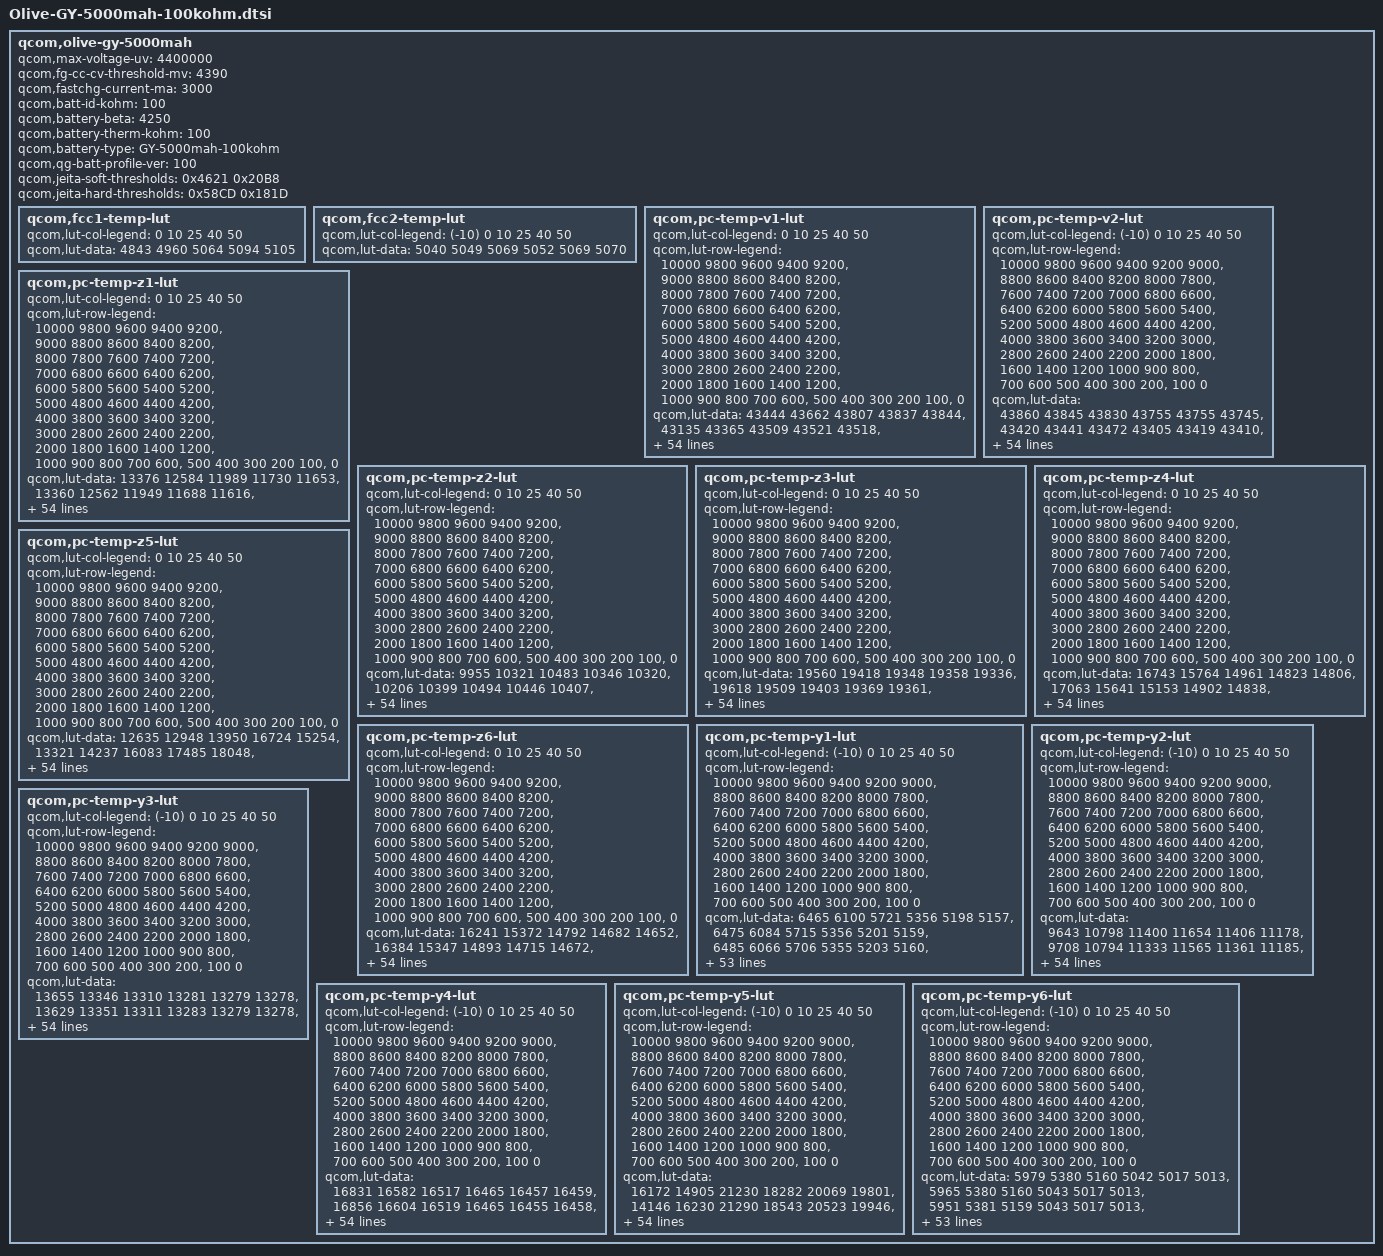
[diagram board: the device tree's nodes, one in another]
/* Copyright (c) 2018, The Linux Foundation. All rights reserved.
 * Copyright (C) 2021 XiaoMi, Inc.
 *
 * This program is free software; you can redistribute it and/or modify
 * it under the terms of the GNU General Public License version 2 and
 * only version 2 as published by the Free Software Foundation.
 *
 * This program is distributed in the hope that it will be useful,
 * but WITHOUT ANY WARRANTY; without even the implied warranty of
 * MERCHANTABILITY or FITNESS FOR A PARTICULAR PURPOSE.  See the
 * GNU General Public License for more details.
 */

qcom,olive-gy-5000mah {
	/* Peony-GY-5000mah-100kohm_Master_2018.12.27 */
	qcom,max-voltage-uv = <4400000>;
	qcom,fg-cc-cv-threshold-mv = <4390>;
	qcom,fastchg-current-ma = <3000>;
	qcom,batt-id-kohm = <100>;
	qcom,battery-beta = <4250>;
	qcom,battery-therm-kohm = <100>;
	qcom,battery-type =
		"GY-5000mah-100kohm";
	qcom,qg-batt-profile-ver = <100>;

/*	qcom,jeita-fcc-ranges = <0   50   400000
				 51  100  1200000
				 101 150  1950000
				 151 450  2000000
				 451 550  1000000
				 551 600  0>;
	qcom,jeita-fv-ranges =  <0   50   4400000
				 51  100  4400000
				 101 150  4400000
				 151 450  4400000
				 451 550  4100000
				 551 600  4100000>;*/

	/* COOL = 15 DegC, WARM = 45 DegC */
	qcom,jeita-soft-thresholds = <0x4621 0x20B8>;
	/* COLD = 0 DegC, HOT = 55 DegC */
	qcom,jeita-hard-thresholds = <0x58CD 0x181D>;

	qcom,fcc1-temp-lut {
		qcom,lut-col-legend = <0 10 25 40 50>;
		qcom,lut-data = <4843 4960 5064 5094 5105>;
	};

	qcom,fcc2-temp-lut {
		qcom,lut-col-legend = <(-10) 0 10 25 40 50>;
		qcom,lut-data = <5040 5049 5069 5052 5069 5070>;
	};

	qcom,pc-temp-v1-lut {
		qcom,lut-col-legend = <0 10 25 40 50>;
		qcom,lut-row-legend = <10000 9800 9600 9400 9200>,
			<9000 8800 8600 8400 8200>,
			<8000 7800 7600 7400 7200>,
			<7000 6800 6600 6400 6200>,
			<6000 5800 5600 5400 5200>,
			<5000 4800 4600 4400 4200>,
			<4000 3800 3600 3400 3200>,
			<3000 2800 2600 2400 2200>,
			<2000 1800 1600 1400 1200>,
			<1000 900 800 700 600>,
			<500 400 300 200 100>,
			<0>;
		qcom,lut-data = <43444 43662 43807 43837 43844>,
			<43135 43365 43509 43521 43518>,
			<42862 43088 43238 43251 43245>,
			<42607 42832 42978 42997 42993>,
			<42368 42590 42726 42749 42748>,
			<42143 42354 42483 42510 42510>,
			<41926 42124 42247 42276 42277>,
			<41711 41900 42020 42042 42042>,
			<41502 41678 41796 41812 41812>,
			<41314 41462 41568 41584 41587>,
			<41165 41270 41344 41359 41366>,
			<41006 41114 41146 41143 41149>,
			<40760 40947 40979 40939 40934>,
			<40419 40685 40792 40739 40726>,
			<40142 40347 40517 40529 40524>,
			<39960 40101 40221 40318 40330>,
			<39815 39950 40035 40131 40147>,
			<39689 39823 39912 39967 39977>,
			<39583 39696 39790 39812 39814>,
			<39478 39577 39653 39665 39662>,
			<39360 39452 39507 39519 39516>,
			<39241 39320 39341 39334 39334>,
			<39126 39180 39153 39081 39078>,
			<39014 39011 38961 38861 38850>,
			<38907 38811 38752 38719 38716>,
			<38807 38643 38570 38606 38612>,
			<38711 38504 38475 38504 38511>,
			<38620 38394 38414 38413 38412>,
			<38530 38325 38355 38331 38322>,
			<38447 38276 38292 38256 38244>,
			<38378 38236 38232 38190 38174>,
			<38316 38204 38179 38129 38109>,
			<38265 38175 38131 38075 38052>,
			<38225 38147 38086 38024 37997>,
			<38191 38122 38046 37980 37948>,
			<38158 38095 38008 37937 37901>,
			<38129 38069 37973 37892 37850>,
			<38096 38037 37939 37847 37798>,
			<38055 37989 37890 37789 37733>,
			<38003 37914 37811 37708 37644>,
			<37931 37822 37715 37611 37541>,
			<37814 37710 37609 37506 37434>,
			<37675 37578 37484 37384 37313>,
			<37513 37415 37326 37224 37153>,
			<37373 37271 37178 37083 37011>,
			<37260 37170 37076 36993 36932>,
			<37219 37135 37051 36966 36908>,
			<37184 37119 37028 36944 36885>,
			<37155 37096 37009 36924 36866>,
			<37118 37067 36980 36891 36823>,
			<36978 36919 36810 36684 36588>,
			<36569 36495 36395 36262 36161>,
			<35999 35931 35828 35692 35592>,
			<35231 35161 35051 34912 34809>,
			<34016 33956 33853 33702 33594>,
			<30000 30000 30000 30000 30000>;
	};

	qcom,pc-temp-v2-lut {
		qcom,lut-col-legend = <(-10) 0 10 25 40 50>;
		qcom,lut-row-legend = <10000 9800 9600 9400 9200 9000>,
			<8800 8600 8400 8200 8000 7800>,
			<7600 7400 7200 7000 6800 6600>,
			<6400 6200 6000 5800 5600 5400>,
			<5200 5000 4800 4600 4400 4200>,
			<4000 3800 3600 3400 3200 3000>,
			<2800 2600 2400 2200 2000 1800>,
			<1600 1400 1200 1000 900 800>,
			<700 600 500 400 300 200>,
			<100 0>;
		qcom,lut-data = <43860 43845 43830 43755 43755 43745>,
			<43420 43441 43472 43405 43419 43410>,
			<43036 43086 43149 43088 43112 43104>,
			<42715 42788 42865 42810 42838 42831>,
			<42443 42538 42617 42567 42594 42588>,
			<42203 42299 42378 42332 42357 42352>,
			<41999 42062 42141 42096 42120 42116>,
			<41807 41831 41909 41863 41887 41884>,
			<41568 41604 41682 41636 41658 41654>,
			<41275 41378 41459 41411 41432 41427>,
			<41079 41177 41248 41195 41210 41205>,
			<41011 41022 41062 40999 40994 40988>,
			<40951 40866 40876 40804 40782 40775>,
			<40702 40623 40646 40577 40574 40571>,
			<40059 40275 40379 40320 40369 40370>,
			<39605 39970 40136 40106 40177 40180>,
			<39434 39736 39926 39946 40001 39997>,
			<39306 39535 39733 39805 39833 39824>,
			<39154 39362 39554 39660 39673 39661>,
			<38996 39213 39387 39519 39520 39509>,
			<38840 39061 39213 39352 39351 39344>,
			<38687 38896 39018 39129 39156 39162>,
			<38542 38737 38834 38900 38957 38974>,
			<38411 38596 38683 38716 38763 38776>,
			<38291 38467 38549 38555 38574 38577>,
			<38197 38344 38428 38423 38431 38428>,
			<38127 38222 38317 38317 38324 38320>,
			<38068 38115 38216 38225 38232 38227>,
			<38012 38036 38128 38140 38145 38138>,
			<37962 37972 38048 38063 38066 38058>,
			<37913 37920 37976 37995 37998 37988>,
			<37864 37876 37908 37932 37939 37927>,
			<37815 37839 37853 37876 37882 37870>,
			<37764 37807 37809 37824 37825 37814>,
			<37712 37778 37773 37777 37767 37758>,
			<37660 37740 37739 37730 37700 37683>,
			<37607 37691 37707 37683 37623 37585>,
			<37552 37635 37671 37631 37543 37488>,
			<37491 37576 37623 37566 37469 37406>,
			<37428 37511 37562 37490 37395 37329>,
			<37364 37433 37489 37409 37318 37251>,
			<37300 37333 37394 37322 37236 37171>,
			<37234 37227 37276 37210 37122 37060>,
			<37164 37122 37138 37068 36980 36922>,
			<37082 37030 37011 36942 36859 36800>,
			<36984 36934 36921 36879 36812 36757>,
			<36926 36890 36901 36868 36802 36747>,
			<36862 36845 36879 36851 36788 36732>,
			<36793 36789 36849 36827 36765 36708>,
			<36690 36715 36789 36773 36696 36629>,
			<36493 36549 36618 36567 36439 36337>,
			<36136 36190 36182 36095 35935 35828>,
			<35592 35612 35537 35467 35280 35164>,
			<34770 34782 34679 34610 34374 34245>,
			<33376 33455 33434 33276 33046 32880>,
			<28527 28294 28305 28229 28383 28334>;
	};

	qcom,pc-temp-z1-lut {
		qcom,lut-col-legend = <0 10 25 40 50>;
		qcom,lut-row-legend = <10000 9800 9600 9400 9200>,
			<9000 8800 8600 8400 8200>,
			<8000 7800 7600 7400 7200>,
			<7000 6800 6600 6400 6200>,
			<6000 5800 5600 5400 5200>,
			<5000 4800 4600 4400 4200>,
			<4000 3800 3600 3400 3200>,
			<3000 2800 2600 2400 2200>,
			<2000 1800 1600 1400 1200>,
			<1000 900 800 700 600>,
			<500 400 300 200 100>,
			<0>;
		qcom,lut-data = <13376 12584 11989 11730 11653>,
			<13360 12562 11949 11688 11616>,
			<13341 12545 11931 11676 11606>,
			<13316 12531 11922 11669 11600>,
			<13301 12521 11915 11665 11597>,
			<13300 12515 11909 11662 11595>,
			<13306 12504 11905 11660 11595>,
			<13308 12495 11903 11659 11596>,
			<13310 12494 11901 11658 11598>,
			<13307 12496 11903 11659 11600>,
			<13294 12495 11906 11661 11602>,
			<13274 12485 11907 11662 11603>,
			<13249 12471 11906 11663 11603>,
			<13215 12453 11905 11663 11603>,
			<13183 12431 11895 11663 11603>,
			<13151 12425 11881 11661 11604>,
			<13127 12428 11880 11660 11604>,
			<13127 12434 11887 11662 11606>,
			<13148 12441 11894 11664 11607>,
			<13162 12453 11900 11665 11608>,
			<13154 12465 11905 11667 11609>,
			<13137 12475 11909 11668 11610>,
			<13131 12483 11911 11669 11611>,
			<13124 12488 11914 11670 11611>,
			<13122 12492 11917 11672 11613>,
			<13140 12494 11920 11674 11615>,
			<13179 12500 11923 11677 11617>,
			<13195 12508 11926 11680 11620>,
			<13185 12511 11930 11682 11623>,
			<13174 12512 11933 11686 11625>,
			<13176 12513 11937 11689 11627>,
			<13185 12520 11941 11692 11629>,
			<13192 12529 11945 11694 11631>,
			<13200 12540 11950 11697 11633>,
			<13209 12554 11957 11700 11635>,
			<13222 12568 11965 11703 11638>,
			<13247 12580 11974 11707 11641>,
			<13267 12592 11983 11710 11643>,
			<13273 12602 11990 11713 11646>,
			<13276 12611 11993 11716 11648>,
			<13281 12619 11996 11720 11650>,
			<13295 12628 12000 11724 11652>,
			<13297 12633 12004 11729 11655>,
			<13249 12622 12009 11732 11657>,
			<13265 12629 12017 11735 11659>,
			<13292 12643 12024 11736 11660>,
			<13308 12647 12021 11736 11659>,
			<13316 12632 12025 11737 11659>,
			<13298 12631 12023 11738 11661>,
			<13277 12638 12037 11742 11665>,
			<13282 12658 12039 11749 11670>,
			<13306 12651 12048 11757 11675>,
			<13288 12695 12060 11767 11684>,
			<13350 12713 12097 11782 11697>,
			<13350 12713 12097 11782 11697>,
			<13350 12713 12097 11782 11697>;
	};

	qcom,pc-temp-z2-lut {
		qcom,lut-col-legend = <0 10 25 40 50>;
		qcom,lut-row-legend = <10000 9800 9600 9400 9200>,
			<9000 8800 8600 8400 8200>,
			<8000 7800 7600 7400 7200>,
			<7000 6800 6600 6400 6200>,
			<6000 5800 5600 5400 5200>,
			<5000 4800 4600 4400 4200>,
			<4000 3800 3600 3400 3200>,
			<3000 2800 2600 2400 2200>,
			<2000 1800 1600 1400 1200>,
			<1000 900 800 700 600>,
			<500 400 300 200 100>,
			<0>;
		qcom,lut-data = <9955 10321 10483 10346 10320>,
			<10206 10399 10494 10446 10407>,
			<10190 10431 10575 10529 10509>,
			<10138 10414 10608 10610 10572>,
			<10124 10392 10598 10616 10577>,
			<10130 10373 10575 10594 10550>,
			<10137 10356 10637 10566 10527>,
			<10145 10340 11160 10518 10521>,
			<10153 10325 11560 10476 10516>,
			<10164 10310 11404 10480 10497>,
			<10183 10304 11098 10504 10445>,
			<10201 10392 11062 10514 10421>,
			<10208 10490 11305 10491 10453>,
			<10209 10463 11454 10468 10493>,
			<10207 10357 11142 10487 10499>,
			<10195 10313 10685 10537 10499>,
			<10180 10318 10575 10547 10493>,
			<10170 10328 10553 10478 10454>,
			<10162 10350 10546 10420 10418>,
			<10158 10394 10577 10433 10424>,
			<10156 10434 10636 10477 10451>,
			<10155 10468 10698 10572 10521>,
			<10155 10502 10776 10853 10835>,
			<10156 10540 10808 11036 11074>,
			<10158 10582 10748 10854 10918>,
			<10162 10597 10667 10559 10624>,
			<10171 10584 10640 10543 10569>,
			<10183 10570 10623 10741 10627>,
			<10201 10577 10618 10857 10664>,
			<10221 10608 10633 10745 10553>,
			<10239 10625 10653 10580 10378>,
			<10255 10626 10664 10522 10324>,
			<10270 10626 10672 10492 10305>,
			<10284 10628 10682 10478 10306>,
			<10298 10633 10696 10478 10331>,
			<10312 10640 10714 10487 10372>,
			<10326 10653 10734 10509 10430>,
			<10339 10673 10759 10554 10513>,
			<10304 10701 10785 10600 10568>,
			<10229 10744 10820 10662 10605>,
			<10222 10772 10846 10705 10627>,
			<10275 10782 10856 10695 10619>,
			<10311 10788 10862 10676 10604>,
			<10334 10792 10860 10722 10607>,
			<9935 10894 10871 10724 10610>,
			<9845 11000 10909 10673 10607>,
			<9845 10996 10883 10678 10595>,
			<9868 11428 10883 10701 10605>,
			<9872 11696 10904 10701 10649>,
			<9952 11776 10951 10811 10727>,
			<9929 11691 10930 10738 10629>,
			<9791 11079 10876 10565 10428>,
			<9875 10983 10780 10486 10353>,
			<9585 10940 10681 10408 10259>,
			<9585 10940 10681 10408 10259>,
			<9585 10940 10681 10408 10259>;
	};

	qcom,pc-temp-z3-lut {
		qcom,lut-col-legend = <0 10 25 40 50>;
		qcom,lut-row-legend = <10000 9800 9600 9400 9200>,
			<9000 8800 8600 8400 8200>,
			<8000 7800 7600 7400 7200>,
			<7000 6800 6600 6400 6200>,
			<6000 5800 5600 5400 5200>,
			<5000 4800 4600 4400 4200>,
			<4000 3800 3600 3400 3200>,
			<3000 2800 2600 2400 2200>,
			<2000 1800 1600 1400 1200>,
			<1000 900 800 700 600>,
			<500 400 300 200 100>,
			<0>;
		qcom,lut-data = <19560 19418 19348 19358 19336>,
			<19618 19509 19403 19369 19361>,
			<19603 19562 19424 19383 19373>,
			<19574 19572 19434 19390 19379>,
			<19566 19578 19435 19391 19382>,
			<19567 19579 19435 19391 19384>,
			<19570 19576 19438 19391 19385>,
			<19573 19572 19448 19390 19387>,
			<19578 19566 19456 19388 19388>,
			<19582 19557 19450 19386 19386>,
			<19586 19551 19440 19383 19379>,
			<19591 19543 19437 19379 19374>,
			<19602 19538 19437 19372 19372>,
			<19622 19536 19435 19367 19370>,
			<19631 19530 19428 19368 19369>,
			<19623 19521 19419 19371 19366>,
			<19609 19501 19410 19371 19363>,
			<19598 19481 19399 19365 19358>,
			<19589 19473 19391 19357 19352>,
			<19582 19469 19385 19352 19347>,
			<19580 19466 19382 19348 19342>,
			<19580 19463 19384 19349 19342>,
			<19582 19461 19394 19364 19355>,
			<19586 19464 19399 19374 19364>,
			<19591 19475 19396 19361 19352>,
			<19594 19480 19391 19340 19330>,
			<19597 19478 19387 19341 19331>,
			<19599 19476 19383 19368 19366>,
			<19600 19475 19382 19384 19388>,
			<19601 19474 19385 19383 19384>,
			<19599 19473 19390 19381 19376>,
			<19595 19471 19392 19378 19370>,
			<19589 19468 19394 19373 19364>,
			<19582 19465 19394 19367 19359>,
			<19574 19461 19393 19362 19351>,
			<19565 19457 19391 19357 19343>,
			<19556 19453 19388 19352 19338>,
			<19544 19450 19383 19348 19335>,
			<19510 19446 19380 19347 19334>,
			<19460 19444 19379 19346 19334>,
			<19443 19441 19377 19346 19335>,
			<19441 19436 19374 19344 19335>,
			<19438 19432 19370 19341 19336>,
			<19431 19430 19369 19345 19339>,
			<19314 19415 19366 19344 19341>,
			<19275 19395 19361 19337 19334>,
			<19271 19392 19353 19332 19326>,
			<19271 19308 19352 19329 19323>,
			<19270 19293 19348 19328 19316>,
			<19266 19275 19347 19318 19310>,
			<19266 19297 19346 19330 19324>,
			<19274 19382 19351 19340 19338>,
			<19298 19364 19348 19342 19336>,
			<19282 19330 19354 19343 19337>,
			<19282 19330 19354 19343 19337>,
			<19282 19330 19354 19343 19337>;
	};

	qcom,pc-temp-z4-lut {
		qcom,lut-col-legend = <0 10 25 40 50>;
		qcom,lut-row-legend = <10000 9800 9600 9400 9200>,
			<9000 8800 8600 8400 8200>,
			<8000 7800 7600 7400 7200>,
			<7000 6800 6600 6400 6200>,
			<6000 5800 5600 5400 5200>,
			<5000 4800 4600 4400 4200>,
			<4000 3800 3600 3400 3200>,
			<3000 2800 2600 2400 2200>,
			<2000 1800 1600 1400 1200>,
			<1000 900 800 700 600>,
			<500 400 300 200 100>,
			<0>;
		qcom,lut-data = <16743 15764 14961 14823 14806>,
			<17063 15641 15153 14902 14838>,
			<16869 15508 15054 14875 14829>,
			<16485 15354 14940 14827 14802>,
			<16186 15193 14881 14795 14780>,
			<15941 15076 14835 14771 14760>,
			<15738 14992 14788 14751 14743>,
			<15593 14927 14734 14734 14727>,
			<15476 14882 14698 14721 14713>,
			<15367 14847 14690 14710 14704>,
			<15255 14809 14687 14700 14698>,
			<15162 14755 14678 14694 14693>,
			<15111 14715 14649 14689 14688>,
			<15077 14717 14631 14685 14684>,
			<15041 14736 14660 14682 14681>,
			<14992 14742 14704 14680 14678>,
			<14941 14729 14707 14677 14675>,
			<14902 14711 14680 14672 14673>,
			<14870 14697 14664 14667 14670>,
			<14845 14683 14663 14663 14666>,
			<14824 14678 14663 14661 14661>,
			<14808 14679 14666 14666 14664>,
			<14792 14679 14684 14711 14713>,
			<14777 14691 14709 14754 14760>,
			<14765 14729 14757 14777 14778>,
			<14755 14757 14802 14792 14789>,
			<14747 14780 14801 14786 14782>,
			<14743 14798 14779 14743 14729>,
			<14741 14795 14758 14708 14690>,
			<14740 14779 14740 14696 14684>,
			<14739 14762 14723 14687 14681>,
			<14738 14747 14709 14681 14678>,
			<14736 14732 14696 14677 14674>,
			<14732 14719 14687 14674 14671>,
			<14725 14707 14682 14671 14670>,
			<14718 14697 14679 14669 14669>,
			<14709 14687 14674 14669 14669>,
			<14704 14678 14670 14669 14669>,
			<14720 14675 14670 14669 14670>,
			<14754 14674 14672 14674 14678>,
			<14762 14672 14674 14679 14686>,
			<14755 14669 14670 14676 14682>,
			<14750 14666 14663 14670 14675>,
			<14747 14663 14662 14670 14677>,
			<14828 14653 14654 14665 14672>,
			<14856 14645 14637 14646 14650>,
			<14851 14643 14635 14642 14646>,
			<14845 14728 14625 14632 14636>,
			<14839 14739 14620 14617 14624>,
			<14836 14755 14616 14618 14618>,
			<14835 14733 14628 14631 14640>,
			<14849 14655 14638 14639 14648>,
			<14841 14685 14646 14643 14654>,
			<14879 14735 14645 14646 14656>,
			<14879 14735 14645 14646 14656>,
			<14879 14735 14645 14646 14656>;
	};

	qcom,pc-temp-z5-lut {
		qcom,lut-col-legend = <0 10 25 40 50>;
		qcom,lut-row-legend = <10000 9800 9600 9400 9200>,
			<9000 8800 8600 8400 8200>,
			<8000 7800 7600 7400 7200>,
			<7000 6800 6600 6400 6200>,
			<6000 5800 5600 5400 5200>,
			<5000 4800 4600 4400 4200>,
			<4000 3800 3600 3400 3200>,
			<3000 2800 2600 2400 2200>,
			<2000 1800 1600 1400 1200>,
			<1000 900 800 700 600>,
			<500 400 300 200 100>,
			<0>;
		qcom,lut-data = <12635 12948 13950 16724 15254>,
			<13321 14237 16083 17485 18048>,
			<13961 15265 17400 19047 20157>,
			<14582 15968 18497 20427 21430>,
			<15144 16526 19398 21266 22551>,
			<15697 17183 20211 21834 23491>,
			<16165 17987 21558 22358 24446>,
			<16491 18824 24203 22856 26139>,
			<16753 19588 26609 23376 27805>,
			<17028 20320 27953 24190 27913>,
			<17305 21290 29196 25256 27397>,
			<17614 23902 31465 25600 27153>,
			<18082 26453 38373 25009 28041>,
			<18742 27752 42852 24419 29436>,
			<19132 29407 39673 25956 30566>,
			<19247 29401 34097 29764 31651>,
			<19318 27059 31344 30902 31920>,
			<19341 24936 29576 29655 30729>,
			<19435 25873 28892 28420 29590>,
			<19642 29364 29841 28189 29632>,
			<20131 32240 32037 28416 29968>,
			<21010 33968 37204 30913 31464>,
			<22110 36106 49031 43554 40744>,
			<23800 43497 54609 52240 47979>,
			<25925 59489 46976 40972 38575>,
			<28408 65535 36005 22697 21154>,
			<31476 61517 30477 19875 18274>,
			<34895 54471 26417 23234 24491>,
			<39565 50797 25145 26433 29198>,
			<43666 48172 26020 28387 30006>,
			<45186 46202 27646 30123 30511>,
			<46151 44480 29973 31703 31267>,
			<46506 43206 33559 33231 32355>,
			<45564 42779 37145 34492 32823>,
			<43623 42710 41362 35680 31834>,
			<41746 42904 44177 36470 30643>,
			<39698 43510 44109 36456 30584>,
			<37040 44502 43592 36172 30760>,
			<31119 46089 43202 35796 30820>,
			<23308 48775 43022 35182 30534>,
			<21147 50087 42675 34266 30064>,
			<23073 46706 39973 32206 29402>,
			<24203 43792 36605 29916 28745>,
			<24295 44688 36805 33063 31919>,
			<15188 41948 37886 34598 35583>,
			<11871 32758 39032 31237 32125>,
			<11777 31755 31337 27297 25227>,
			<11764 13630 33448 27988 25484>,
			<11753 12893 32719 33863 26633>,
			<11721 12316 33738 26999 25972>,
			<11782 13433 28855 32013 30680>,
			<11946 23934 25540 27093 26201>,
			<12327 19240 21946 24254 21310>,
			<11762 14039 22225 21532 18748>,
			<11762 14039 22225 21532 18748>,
			<11762 14039 22225 21532 18748>;
	};

	qcom,pc-temp-z6-lut {
		qcom,lut-col-legend = <0 10 25 40 50>;
		qcom,lut-row-legend = <10000 9800 9600 9400 9200>,
			<9000 8800 8600 8400 8200>,
			<8000 7800 7600 7400 7200>,
			<7000 6800 6600 6400 6200>,
			<6000 5800 5600 5400 5200>,
			<5000 4800 4600 4400 4200>,
			<4000 3800 3600 3400 3200>,
			<3000 2800 2600 2400 2200>,
			<2000 1800 1600 1400 1200>,
			<1000 900 800 700 600>,
			<500 400 300 200 100>,
			<0>;
		qcom,lut-data = <16241 15372 14792 14682 14652>,
			<16384 15347 14893 14715 14672>,
			<16281 15308 14856 14706 14671>,
			<16077 15249 14813 14690 14663>,
			<15926 15170 14787 14678 14656>,
			<15811 15112 14765 14667 14648>,
			<15717 15069 14747 14658 14642>,
			<15650 15034 14730 14650 14636>,
			<15596 15007 14718 14643 14631>,
			<15545 14985 14711 14637 14626>,
			<15494 14962 14705 14632 14620>,
			<15448 14932 14696 14627 14615>,
			<15414 14908 14683 14621 14612>,
			<15388 14901 14676 14617 14609>,
			<15360 14897 14682 14616 14607>,
			<15326 14891 14691 14616 14604>,
			<15293 14876 14689 14615 14601>,
			<15270 14861 14673 14609 14597>,
			<15251 14853 14662 14603 14593>,
			<15237 14848 14660 14599 14588>,
			<15227 14847 14658 14596 14584>,
			<15218 14847 14661 14599 14586>,
			<15214 14848 14674 14629 14615>,
			<15212 14856 14689 14650 14639>,
			<15212 14879 14709 14650 14638>,
			<15213 14895 14726 14650 14634>,
			<15215 14906 14725 14648 14631>,
			<15218 14913 14714 14644 14628>,
			<15221 14912 14706 14639 14625>,
			<15225 14907 14701 14635 14620>,
			<15226 14901 14697 14630 14615>,
			<15226 14895 14693 14626 14611>,
			<15226 14889 14689 14621 14607>,
			<15224 14884 14686 14617 14602>,
			<15221 14879 14684 14614 14598>,
			<15217 14876 14682 14611 14593>,
			<15214 14873 14680 14608 14590>,
			<15211 14870 14677 14606 14588>,
			<15206 14870 14676 14605 14588>,
			<15199 14872 14678 14607 14592>,
			<15198 14873 14679 14610 14595>,
			<15200 14873 14677 14608 14594>,
			<15202 14873 14674 14604 14591>,
			<15201 14875 14674 14607 14594>,
			<15186 14869 14671 14604 14593>,
			<15181 14858 14663 14593 14580>,
			<15178 14856 14657 14589 14575>,
			<15175 14850 14654 14583 14569>,
			<15173 14848 14650 14577 14560>,
			<15172 14849 14648 14572 14554>,
			<15179 14857 14655 14585 14572>,
			<15194 14872 14666 14596 14585>,
			<15213 14885 14671 14600 14589>,
			<15240 14903 14681 14606 14594>,
			<15240 14903 14681 14606 14594>,
			<15240 14903 14681 14606 14594>;
	};

	qcom,pc-temp-y1-lut {
		qcom,lut-col-legend = <(-10) 0 10 25 40 50>;
		qcom,lut-row-legend = <10000 9800 9600 9400 9200 9000>,
			<8800 8600 8400 8200 8000 7800>,
			<7600 7400 7200 7000 6800 6600>,
			<6400 6200 6000 5800 5600 5400>,
			<5200 5000 4800 4600 4400 4200>,
			<4000 3800 3600 3400 3200 3000>,
			<2800 2600 2400 2200 2000 1800>,
			<1600 1400 1200 1000 900 800>,
			<700 600 500 400 300 200>,
			<100 0>;
		qcom,lut-data = <6465 6100 5721 5356 5198 5157>,
			<6475 6084 5715 5356 5201 5159>,
			<6485 6066 5706 5355 5203 5160>,
			<6493 6050 5697 5354 5204 5161>,
			<6499 6039 5689 5354 5205 5162>,
			<6501 6034 5684 5354 5206 5162>,
			<6503 6038 5681 5353 5205 5162>,
			<6507 6043 5679 5352 5204 5161>,
			<6507 6042 5678 5351 5204 5161>,
			<6507 6036 5678 5350 5204 5161>,
			<6509 6033 5679 5350 5205 5161>,
			<6516 6035 5679 5348 5204 5161>,
			<6523 6038 5680 5348 5203 5162>,
			<6522 6041 5681 5348 5203 5162>,
			<6513 6048 5684 5349 5202 5162>,
			<6514 6051 5687 5351 5203 5161>,
			<6532 6056 5692 5354 5203 5162>,
			<6549 6063 5697 5357 5204 5163>,
			<6542 6067 5694 5357 5204 5163>,
			<6512 6071 5686 5354 5204 5163>,
			<6498 6072 5683 5352 5204 5164>,
			<6497 6072 5683 5355 5205 5164>,
			<6496 6072 5683 5358 5206 5165>,
			<6507 6068 5686 5360 5207 5166>,
			<6540 6060 5691 5362 5208 5167>,
			<6553 6060 5695 5363 5210 5168>,
			<6533 6069 5699 5366 5211 5169>,
			<6510 6075 5701 5369 5213 5171>,
			<6503 6075 5699 5372 5215 5173>,
			<6500 6075 5694 5375 5217 5175>,
			<6500 6075 5692 5378 5220 5176>,
			<6512 6079 5694 5381 5222 5178>,
			<6522 6082 5696 5384 5224 5179>,
			<6521 6083 5700 5387 5227 5180>,
			<6518 6083 5705 5390 5229 5182>,
			<6516 6083 5706 5392 5230 5183>,
			<6513 6080 5703 5393 5231 5184>,
			<6510 6080 5701 5394 5232 5185>,
			<6504 6074 5704 5396 5233 5187>,
			<6494 6062 5708 5399 5234 5188>,
			<6492 6060 5713 5402 5235 5189>,
			<6501 6069 5719 5405 5237 5190>,
			<6504 6073 5719 5408 5240 5191>,
			<6495 6074 5718 5411 5243 5194>,
			<6514 6093 5728 5414 5247 5197>,
			<6602 6110 5743 5423 5251 5200>,
			<6569 6116 5745 5428 5252 5199>,
			<6546 6115 5743 5428 5251 5199>,
			<6552 6120 5750 5429 5251 5198>,
			<6558 6108 5757 5428 5250 5199>,
			<6581 6123 5761 5429 5253 5202>,
			<6594 6140 5777 5436 5260 5206>,
			<6607 6162 5778 5461 5269 5213>,
			<6636 6208 5801 5484 5282 5224>,
			<6636 6208 5801 5484 5282 5224>,
			<6636 6208 5801 5484 5282 5224>;
	};

	qcom,pc-temp-y2-lut {
		qcom,lut-col-legend = <(-10) 0 10 25 40 50>;
		qcom,lut-row-legend = <10000 9800 9600 9400 9200 9000>,
			<8800 8600 8400 8200 8000 7800>,
			<7600 7400 7200 7000 6800 6600>,
			<6400 6200 6000 5800 5600 5400>,
			<5200 5000 4800 4600 4400 4200>,
			<4000 3800 3600 3400 3200 3000>,
			<2800 2600 2400 2200 2000 1800>,
			<1600 1400 1200 1000 900 800>,
			<700 600 500 400 300 200>,
			<100 0>;
		qcom,lut-data = <9643 10798 11400 11654 11406 11178>,
			<9708 10794 11333 11565 11361 11185>,
			<9811 10786 11268 11477 11306 11183>,
			<9908 10776 11208 11395 11250 11173>,
			<9993 10769 11153 11325 11199 11157>,
			<10062 10766 11107 11270 11164 11136>,
			<10106 10767 11065 11226 11137 11098>,
			<10151 10767 11031 11193 11113 11053>,
			<10296 10763 11011 11173 11091 11021>,
			<10661 10750 10998 11149 11067 10993>,
			<10850 10745 10987 11125 11055 10984>,
			<10752 10912 10973 11088 11034 10996>,
			<10557 11124 10964 11055 11010 11011>,
			<10296 11130 11004 11061 11004 11002>,
			<9908 11059 11142 11101 11000 10966>,
			<9722 11025 11231 11150 10999 10944>,
			<9706 11053 11272 11208 11020 10933>,
			<9698 11096 11297 11277 11059 10926>,
			<9691 11130 11304 11359 11119 10935>,
			<9687 11163 11308 11455 11213 10968>,
			<9684 11191 11316 11492 11293 11028>,
			<9683 11214 11347 11481 11370 11211>,
			<9683 11234 11387 11467 11417 11362>,
			<9682 11256 11418 11472 11391 11354>,
			<9681 11278 11446 11489 11331 11326>,
			<9679 11287 11467 11502 11316 11321>,
			<9678 11288 11482 11526 11350 11353>,
			<9676 11287 11496 11553 11389 11382>,
			<9674 11288 11517 11569 11420 11387>,
			<9672 11288 11541 11585 11457 11391>,
			<9671 11284 11548 11595 11486 11409>,
			<9669 11249 11547 11603 11511 11490>,
			<9668 11206 11543 11607 11528 11548>,
			<9666 11181 11539 11602 11534 11529>,
			<9665 11159 11531 11588 11534 11488>,
			<9664 11044 11517 11573 11511 11455>,
			<9663 10344 11488 11536 11435 11426>,
			<9663 9763 11455 11509 11380 11399>,
			<9662 9719 11424 11511 11369 11373>,
			<9661 9701 11389 11516 11365 11347>,
			<9661 9690 11339 11517 11371 11316>,
			<9661 9682 11269 11505 11388 11280>,
			<9660 9676 11184 11485 11378 11287>,
			<9660 9670 11080 11442 11353 11306>,
			<9660 9667 10972 11397 11295 11216>,
			<9659 9665 10132 11346 11196 11066>,
			<9659 9663 10794 11326 11184 11023>,
			<9659 9662 10750 11288 11172 11049>,
			<9659 9660 10707 11302 11215 11051>,
			<9658 9660 10661 11309 11244 11062>,
			<9658 9659 10581 11276 11180 11001>,
			<9658 9658 10051 11179 11066 10919>,
			<9658 9657 9715 11055 10974 10806>,
			<9657 9657 9677 10944 10849 10623>,
			<9657 9657 9677 10944 10849 10623>,
			<9657 9657 9677 10944 10849 10623>;
	};

	qcom,pc-temp-y3-lut {
		qcom,lut-col-legend = <(-10) 0 10 25 40 50>;
		qcom,lut-row-legend = <10000 9800 9600 9400 9200 9000>,
			<8800 8600 8400 8200 8000 7800>,
			<7600 7400 7200 7000 6800 6600>,
			<6400 6200 6000 5800 5600 5400>,
			<5200 5000 4800 4600 4400 4200>,
			<4000 3800 3600 3400 3200 3000>,
			<2800 2600 2400 2200 2000 1800>,
			<1600 1400 1200 1000 900 800>,
			<700 600 500 400 300 200>,
			<100 0>;
		qcom,lut-data = <13655 13346 13310 13281 13279 13278>,
			<13629 13351 13311 13283 13279 13278>,
			<13602 13357 13312 13284 13279 13278>,
			<13578 13362 13313 13285 13280 13278>,
			<13562 13366 13315 13286 13280 13279>,
			<13555 13370 13316 13287 13281 13279>,
			<13563 13371 13318 13287 13281 13280>,
			<13574 13373 13320 13287 13281 13280>,
			<13567 13378 13321 13287 13282 13281>,
			<13527 13388 13323 13288 13282 13281>,
			<13486 13393 13325 13289 13283 13281>,
			<13451 13388 13327 13292 13283 13282>,
			<13425 13378 13329 13296 13284 13282>,
			<13422 13369 13328 13296 13284 13282>,
			<13426 13358 13326 13295 13284 13282>,
			<13427 13352 13325 13294 13285 13282>,
			<13420 13350 13324 13296 13286 13282>,
			<13409 13348 13324 13297 13288 13283>,
			<13403 13346 13322 13297 13288 13284>,
			<13399 13343 13318 13297 13288 13285>,
			<13397 13340 13314 13296 13288 13286>,
			<13396 13336 13311 13294 13287 13285>,
			<13395 13333 13308 13291 13285 13284>,
			<13390 13330 13307 13288 13282 13281>,
			<13378 13327 13306 13285 13279 13277>,
			<13373 13324 13304 13284 13278 13276>,
			<13380 13320 13302 13284 13278 13276>,
			<13392 13317 13300 13284 13278 13276>,
			<13406 13315 13300 13284 13277 13276>,
			<13424 13314 13300 13284 13277 13275>,
			<13443 13314 13300 13284 13276 13275>,
			<13465 13314 13299 13285 13277 13275>,
			<13489 13314 13299 13285 13277 13275>,
			<13518 13317 13299 13285 13277 13275>,
			<13551 13322 13299 13285 13278 13276>,
			<13588 13324 13300 13285 13278 13276>,
			<13631 13317 13302 13285 13277 13275>,
			<13677 13312 13304 13285 13277 13275>,
			<13723 13318 13306 13285 13278 13275>,
			<13772 13329 13307 13285 13278 13276>,
			<13824 13345 13309 13285 13279 13277>,
			<13881 13373 13310 13286 13280 13278>,
			<13940 13409 13310 13287 13280 13278>,
			<13999 13458 13311 13286 13278 13277>,
			<14056 13524 13312 13286 13276 13275>,
			<14049 13548 13303 13286 13280 13280>,
			<14111 13619 13317 13290 13283 13282>,
			<14178 13691 13323 13292 13285 13283>,
			<14250 13779 13331 13295 13287 13285>,
			<14330 13878 13341 13298 13287 13285>,
			<14407 13965 13348 13296 13284 13282>,
			<14496 14067 13355 13295 13283 13282>,
			<14620 14218 13396 13301 13287 13285>,
			<14916 14391 13483 13310 13293 13292>,
			<14916 14391 13483 13310 13293 13292>,
			<14916 14391 13483 13310 13293 13292>;
	};

	qcom,pc-temp-y4-lut {
		qcom,lut-col-legend = <(-10) 0 10 25 40 50>;
		qcom,lut-row-legend = <10000 9800 9600 9400 9200 9000>,
			<8800 8600 8400 8200 8000 7800>,
			<7600 7400 7200 7000 6800 6600>,
			<6400 6200 6000 5800 5600 5400>,
			<5200 5000 4800 4600 4400 4200>,
			<4000 3800 3600 3400 3200 3000>,
			<2800 2600 2400 2200 2000 1800>,
			<1600 1400 1200 1000 900 800>,
			<700 600 500 400 300 200>,
			<100 0>;
		qcom,lut-data = <16831 16582 16517 16465 16457 16459>,
			<16856 16604 16519 16465 16455 16458>,
			<16888 16625 16522 16465 16454 16456>,
			<16921 16644 16524 16465 16453 16455>,
			<16946 16661 16527 16465 16452 16454>,
			<16956 16674 16529 16465 16452 16453>,
			<16951 16687 16531 16467 16452 16452>,
			<16945 16696 16533 16469 16452 16452>,
			<16951 16693 16537 16472 16453 16452>,
			<16989 16680 16547 16475 16454 16452>,
			<17049 16673 16559 16479 16456 16453>,
			<17249 16776 16572 16483 16458 16454>,
			<17468 16907 16589 16486 16461 16456>,
			<17388 16905 16613 16491 16464 16458>,
			<16978 16831 16645 16498 16468 16461>,
			<16770 16761 16657 16508 16473 16465>,
			<16792 16700 16650 16527 16480 16470>,
			<16818 16656 16639 16551 16488 16476>,
			<16815 16651 16629 16579 16505 16486>,
			<16787 16650 16616 16611 16531 16501>,
			<16755 16647 16597 16620 16539 16512>,
			<16716 16626 16559 16580 16536 16522>,
			<16680 16598 16524 16526 16531 16528>,
			<16664 16582 16509 16493 16508 16509>,
			<16653 16568 16500 16466 16465 16466>,
			<16647 16553 16494 16457 16451 16452>,
			<16643 16529 16491 16456 16451 16452>,
			<16641 16510 16489 16456 16450 16451>,
			<16639 16507 16487 16457 16452 16453>,
			<16639 16505 16486 16460 16457 16457>,
			<16640 16505 16483 16463 16463 16463>,
			<16641 16512 16478 16466 16472 16470>,
			<16643 16522 16475 16469 16479 16478>,
			<16645 16530 16477 16471 16481 16488>,
			<16649 16539 16482 16473 16482 16496>,
			<16652 16556 16489 16473 16480 16493>,
			<16654 16602 16499 16473 16467 16472>,
			<16657 16640 16510 16473 16458 16459>,
			<16664 16651 16520 16471 16459 16460>,
			<16676 16658 16528 16466 16460 16463>,
			<16690 16657 16535 16466 16464 16469>,
			<16707 16638 16540 16473 16473 16482>,
			<16727 16629 16539 16474 16471 16480>,
			<16750 16626 16534 16467 16457 16463>,
			<16757 16632 16525 16462 16441 16440>,
			<16725 16634 16554 16462 16450 16455>,
			<16740 16652 16536 16475 16470 16483>,
			<16748 16682 16561 16493 16500 16516>,
			<16763 16713 16596 16524 16535 16552>,
			<16780 16755 16648 16561 16551 16559>,
			<16781 16791 16672 16547 16505 16495>,
			<16772 16786 16658 16505 16469 16469>,
			<16763 16777 16671 16524 16473 16470>,
			<16811 16776 16724 16565 16497 16488>,
			<16811 16776 16724 16565 16497 16488>,
			<16811 16776 16724 16565 16497 16488>;
	};

	qcom,pc-temp-y5-lut {
		qcom,lut-col-legend = <(-10) 0 10 25 40 50>;
		qcom,lut-row-legend = <10000 9800 9600 9400 9200 9000>,
			<8800 8600 8400 8200 8000 7800>,
			<7600 7400 7200 7000 6800 6600>,
			<6400 6200 6000 5800 5600 5400>,
			<5200 5000 4800 4600 4400 4200>,
			<4000 3800 3600 3400 3200 3000>,
			<2800 2600 2400 2200 2000 1800>,
			<1600 1400 1200 1000 900 800>,
			<700 600 500 400 300 200>,
			<100 0>;
		qcom,lut-data = <16172 14905 21230 18282 20069 19801>,
			<14146 16230 21290 18543 20523 19946>,
			<13274 17275 21216 18720 20765 20290>,
			<13276 18032 21039 18821 20850 20710>,
			<13872 18488 20792 18853 20832 21082>,
			<14786 18630 20505 18820 20762 21283>,
			<17090 18284 20158 18295 20518 21508>,
			<19645 17801 19726 17543 20118 21711>,
			<19203 18209 19178 17133 19707 21432>,
			<15669 20175 18451 16513 19211 20477>,
			<13725 21187 17714 16214 18738 19805>,
			<15964 18685 16728 16505 18331 19514>,
			<18906 15527 15934 16866 17910 19228>,
			<18592 16467 16048 16676 17312 18716>,
			<15913 21163 16835 15859 16559 17777>,
			<14533 23407 17968 15449 16289 16994>,
			<14514 22529 20484 15483 16318 16418>,
			<14506 21509 22870 15606 16349 15970>,
			<14676 21661 23494 16012 16147 15666>,
			<15284 22491 23796 17177 15607 15430>,
			<15652 23026 24122 18822 15624 15532>,
			<15753 23285 24526 22342 18617 17837>,
			<15780 23451 24887 25332 21699 20349>,
			<15223 23573 25180 25063 22452 21273>,
			<13685 23861 25424 23753 22886 21868>,
			<13050 23937 25311 23126 22952 21980>,
			<13095 23000 23670 23144 22686 21763>,
			<13167 21940 22322 23245 22264 21393>,
			<13257 21154 22869 23290 21344 20302>,
			<13395 19763 23998 23420 20089 18706>,
			<13518 19086 24397 23704 19851 18345>,
			<13642 18614 24315 25006 20356 18480>,
			<13718 18290 24226 26341 21110 18731>,
			<13726 19112 24069 26891 22396 19909>,
			<13773 20932 23770 27261 23937 21882>,
			<13867 21067 23824 27371 24670 23186>,
			<14079 17446 24608 27373 25178 24222>,
			<14240 14476 25146 27325 25404 24672>,
			<14125 14493 24928 26217 24784 23938>,
			<13836 14712 24436 24167 23894 22879>,
			<13723 14846 23849 23579 23855 22730>,
			<13791 14918 23011 23541 24169 22838>,
			<13920 14785 21669 23058 24085 23958>,
			<14175 14413 20231 21557 23295 25441>,
			<14508 14549 19932 21482 20882 21382>,
			<14562 14174 15023 20432 20137 19395>,
			<14582 14329 18508 21227 19273 17510>,
			<15042 14456 18399 19902 18035 16134>,
			<16065 15050 18338 19385 17266 15642>,
			<16998 16501 18601 18949 16668 15447>,
			<16967 17066 18919 18987 17083 15964>,
			<15406 16319 16851 20884 18670 17199>,
			<14529 14863 14734 20840 19592 17781>,
			<13637 14071 14652 21244 23901 23646>,
			<13637 14071 14652 21244 23901 23646>,
			<13637 14071 14652 21244 23901 23646>;
	};

	qcom,pc-temp-y6-lut {
		qcom,lut-col-legend = <(-10) 0 10 25 40 50>;
		qcom,lut-row-legend = <10000 9800 9600 9400 9200 9000>,
			<8800 8600 8400 8200 8000 7800>,
			<7600 7400 7200 7000 6800 6600>,
			<6400 6200 6000 5800 5600 5400>,
			<5200 5000 4800 4600 4400 4200>,
			<4000 3800 3600 3400 3200 3000>,
			<2800 2600 2400 2200 2000 1800>,
			<1600 1400 1200 1000 900 800>,
			<700 600 500 400 300 200>,
			<100 0>;
		qcom,lut-data = <5979 5380 5160 5042 5017 5013>,
			<5965 5380 5160 5043 5017 5013>,
			<5951 5381 5159 5043 5017 5013>,
			<5938 5382 5159 5044 5017 5013>,
			<5927 5382 5158 5044 5018 5013>,
			<5918 5382 5158 5045 5018 5013>,
			<5913 5382 5158 5046 5019 5014>,
			<5908 5380 5158 5046 5019 5014>,
			<5897 5379 5158 5047 5020 5014>,
			<5877 5378 5161 5049 5020 5015>,
			<5868 5377 5164 5050 5021 5015>,
			<5898 5397 5168 5053 5022 5016>,
			<5938 5421 5172 5056 5023 5017>,
			<5911 5417 5178 5058 5025 5018>,
			<5789 5390 5184 5060 5026 5019>,
			<5727 5367 5186 5062 5028 5020>,
			<5731 5351 5184 5069 5031 5022>,
			<5736 5341 5182 5077 5034 5024>,
			<5735 5337 5178 5085 5040 5027>,
			<5731 5335 5170 5093 5047 5033>,
			<5725 5331 5161 5096 5049 5036>,
			<5719 5324 5148 5083 5047 5037>,
			<5714 5316 5137 5065 5044 5038>,
			<5713 5311 5133 5053 5035 5031>,
			<5713 5308 5130 5044 5020 5016>,
			<5714 5306 5128 5041 5016 5011>,
			<5723 5302 5126 5041 5016 5011>,
			<5738 5300 5125 5041 5016 5011>,
			<5754 5301 5126 5042 5016 5011>,
			<5772 5307 5127 5043 5017 5012>,
			<5792 5314 5128 5045 5019 5013>,
			<5814 5323 5128 5046 5022 5015>,
			<5839 5336 5128 5048 5024 5018>,
			<5866 5352 5130 5049 5025 5021>,
			<5895 5372 5134 5050 5026 5024>,
			<5927 5392 5139 5051 5025 5023>,
			<5962 5414 5146 5052 5022 5017>,
			<6000 5438 5154 5052 5019 5013>,
			<6039 5466 5162 5052 5020 5014>,
			<6080 5499 5170 5051 5020 5015>,
			<6124 5535 5179 5052 5022 5018>,
			<6172 5574 5189 5056 5026 5023>,
			<6222 5621 5200 5057 5026 5022>,
			<6274 5678 5211 5056 5021 5017>,
			<6328 5752 5221 5057 5016 5010>,
			<6326 5780 5230 5059 5022 5017>,
			<6376 5849 5253 5066 5030 5027>,
			<6431 5917 5278 5074 5040 5038>,
			<6492 5998 5311 5085 5051 5049>,
			<6558 6091 5352 5098 5056 5051>,
			<6622 6174 5382 5093 5040 5031>,
			<6696 6256 5402 5083 5030 5024>,
			<6797 6378 5480 5100 5036 5028>,
			<7070 6522 5627 5127 5050 5040>,
			<7070 6522 5627 5127 5050 5040>,
			<7070 6522 5627 5127 5050 5040>;
	};

};
